# CAM_CM2 register map
Vendor: Texas Instruments
Peripheral module from a debugger description file (folder omap4430).
Registers are 32-bit, access per field, reset 0x70000 unless marked. A register's access mark holds for its fields unless they carry their own. Offsets are as the file gives them; lines under a group give offsets from that group; [hi:lo] are bit positions; {n}, {i} and the like mark numbered series; 'fields as' and 'values as' point back to an identical list; <NAME> marks a mode.

## CAM_CM2
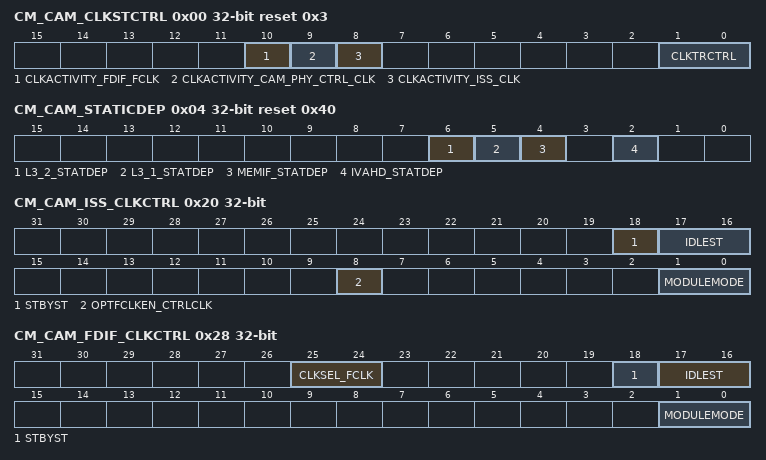
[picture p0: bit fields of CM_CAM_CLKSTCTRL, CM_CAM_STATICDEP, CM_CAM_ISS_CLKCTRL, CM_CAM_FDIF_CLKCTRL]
0x00 CM_CAM_CLKSTCTRL reset 0x3 — This register enables the domain power state transition. It controls the hardware supervised domain power state transition between ON-ACTIVE and ON-INACTIVE states. It also holds 1 status bit per clock input of the domain.
  [10] CLKACTIVITY_FDIF_FCLK ro — This field indicates the state of the FDIF_FCLK clock input of the domain. [warm reset insensitive]
    0=CLKACTIVITY_FDIF_FCLK_0_r (Corresponding clock is definitely gated); 1=CLKACTIVITY_FDIF_FCLK_1_r (Corresponding clock is running or gating/ungating transition is ongoing)
  [9] CLKACTIVITY_CAM_PHY_CTRL_CLK ro — This field indicates the state of the CAM_PHY_CTRL_CLK clock input of the domain. [warm reset insensitive]
    0=CLKACTIVITY_CAM_PHY_CTRL_CLK_0_r (Corresponding clock is definitely gated); 1=CLKACTIVITY_CAM_PHY_CTRL_CLK_1_r (Corresponding clock is running or gating/ungating transition is ongoing)
  [8] CLKACTIVITY_ISS_CLK ro — This field indicates the state of the ISS_CLK clock input of the domain. [warm reset insensitive]
    0=CLKACTIVITY_ISS_CLK_0_r (Corresponding clock is definitely gated); 1=CLKACTIVITY_ISS_CLK_1_r (Corresponding clock is running or gating/ungating transition is ongoing)
  [1:0] CLKTRCTRL rw — Controls the clock state transition of the CAM clock domain.
    0=NO_SLEEP: Sleep transition cannot be initiated. Wakeup transition may however occur.; 1=SW_SLEEP: Start a software forced sleep transition on the domain; 2=SW_WKUP: Start a software forced wake-up transition on the domain; 3=HW_AUTO: Automatic transition is enabled. Sleep and wakeup transition are based upon hardware conditions.
0x04 CM_CAM_STATICDEP access not given reset 0x40 — This register controls the static domain depedencies from CAM domain towards 'target' domains. It is relevant only for domain having system initiator(s).
  [6] L3_2_STATDEP — Static dependency towards L3_2 clock domain (access R Rreturns1s)
    1=L3_2_STATDEP_1_r (Dependency is enabled)
  [5] L3_1_STATDEP rw — Static dependency towards L3_1 clock domain
    0=Dependency is disabled; 1=Dependency is enabled
  [4] MEMIF_STATDEP rw — Static dependency towards MEMIF clock domain
    0=Dependency is disabled; 1=Dependency is enabled
  [2] IVAHD_STATDEP rw — Static dependency towards IVAHD clock domain
    0=Dependency is disabled; 1=Dependency is enabled
0x08 CM_CAM_DYNAMICDEP ro reset 0x0 — This register controls the dynamic domain depedencies from CAM domain towards 'target' domains. It is relevant only for domain having INTRCONN master port(s).
  [6] L3_2_DYNDEP — Dynamic dependency towards L3_2 clock domain
    0=L3_2_DYNDEP_0_r (Dependency is disabled)
0x20 CM_CAM_ISS_CLKCTRL — This register manages the ISS clocks.
  [18] STBYST ro — Module standby status. [warm reset insensitive]
    0=STBYST_0_r (Module is functional (not in standby)); 1=STBYST_1_r (Module is in standby)
  [17:16] IDLEST ro — Module idle status. [warm reset insensitive]
    0=IDLEST_0_r (Module is fully functional, including INTRCONN); 1=IDLEST_1_r (Module is performing transition: wakeup, or sleep, or sleep abortion); 2=IDLEST_2_r (Module is in idle mode (only INTRCONN part). It is functional if using separate functional clock); 3=IDLEST_3_r (Module is disabled and cannot be accessed)
  [8] OPTFCLKEN_CTRLCLK rw — Optional functional clock control for CAM_PHY_CTRL_GCLK 96Mhz clock.
    0=Optional functional clock is disabled; 1=Optional functional clock is enabled
  [1:0] MODULEMODE rw — Control the way mandatory clocks are managed.
    0=Module is disable by software. Any INTRCONN access to module results in an error, except if resulting from a module wakeup (asynchronous wakeup).; 1=MODULEMODE_1_r (Reserved); 2=Module is explicitly enabled. Interface clock (if not used for functions) may be gated according to the clock domain state. Functional clocks are guarantied to stay present. As long as in this configuration, power domain sleep transition cannot happen.; 3=MODULEMODE_3_r (Reserved)
0x28 CM_CAM_FDIF_CLKCTRL — This register manages the FDIF clocks.
  [25:24] CLKSEL_FCLK rw — Select the ration of FDIF_FCLK to FUNC_128M_CLK
    0=FDIF_FCLK is divide by 1 of FUNC_128_CLK, to be used for OPP100; 1=FDIF_FCLK is divide by 2 of FUNC_128_CLK, to be used for OPP50; 2=FDIF_FCLK is divide by 4 of FUNC_128_CLK
  [18] STBYST ro — Module standby status. [warm reset insensitive]
    values as CM_CAM_ISS_CLKCTRL.STBYST
  [17:16] IDLEST ro — Module idle status. [warm reset insensitive]
    values as CM_CAM_ISS_CLKCTRL.IDLEST
  [1:0] MODULEMODE rw — Control the way mandatory clocks are managed.
    values as CM_CAM_ISS_CLKCTRL.MODULEMODE
